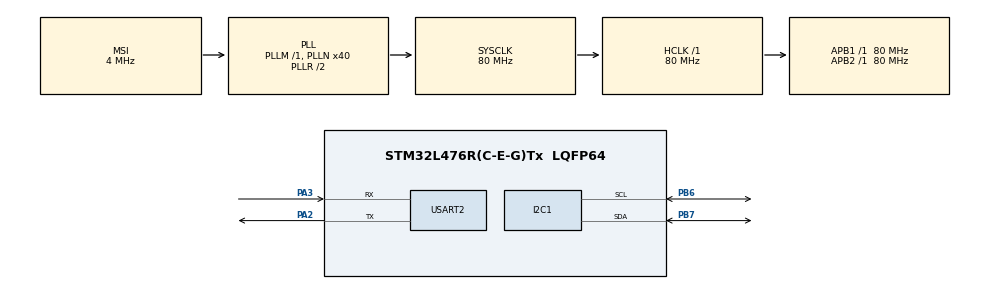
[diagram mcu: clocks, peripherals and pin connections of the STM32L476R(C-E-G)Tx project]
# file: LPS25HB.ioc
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I2C1.Timing=0x10D19CE4
Mcu.Family=STM32L4
Mcu.Name=STM32L476R(C-E-G)Tx
Mcu.Package=LQFP64
NVIC.PriorityGroup=NVIC_PRIORITYGROUP_4
NVIC.USART2_IRQn=true\:15\:0\:true\:false\:true\:true\:true\:true
PA13\ (JTMS-SWDIO).Mode=Serial_Wire
PA13\ (JTMS-SWDIO).Signal=SYS_JTMS-SWDIO
PA14\ (JTCK-SWCLK).Mode=Serial_Wire
PA14\ (JTCK-SWCLK).Signal=SYS_JTCK-SWCLK
PA2.Mode=Asynchronous
PA2.Signal=USART2_TX
PA3.Mode=Asynchronous
PA3.Signal=USART2_RX
PB6.Mode=I2C
PB6.Signal=I2C1_SCL
PB7.Mode=I2C
PB7.Signal=I2C1_SDA
ProjectManager.HeapSize=0x200
ProjectManager.StackSize=0x400
ProjectManager.TargetToolchain=STM32CubeIDE
RCC.AHBFreq_Value=80000000
RCC.APB1Freq_Value=80000000
RCC.APB1TimFreq_Value=80000000
RCC.APB2Freq_Value=80000000
RCC.APB2TimFreq_Value=80000000
RCC.CortexFreq_Value=80000000
RCC.HCLKFreq_Value=80000000
RCC.HSE_VALUE=8000000
RCC.HSI_VALUE=16000000
RCC.LSE_VALUE=32768
RCC.MSI_VALUE=4000000
RCC.PLLN=40
RCC.SYSCLKFreq_VALUE=80000000
RCC.SYSCLKSource=RCC_SYSCLKSOURCE_PLLCLK
RCC.VCOOutputFreq_Value=160000000
USART2.OverrunDisableParam=ADVFEATURE_OVERRUN_DISABLE
USART2.VirtualMode-Asynchronous=VM_ASYNC
board=custom

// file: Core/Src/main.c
/* USER CODE BEGIN Header */
/**
  ******************************************************************************
  * @file           : main.c
  * @brief          : Main program body
  ******************************************************************************
  * @attention
  *
  * Copyright (c) 2026 STMicroelectronics.
  * All rights reserved.
  *
  * This software is licensed under terms that can be found in the LICENSE file
  * in the root directory of this software component.
  * If no LICENSE file comes with this software, it is provided AS-IS.
  *
  ******************************************************************************
  */
/* USER CODE END Header */
#include "main.h"
#include "i2c.h"
#include "usart.h"
#include "gpio.h"

/* USER CODE BEGIN Includes */
#include "stdio.h"

#include "my_uart.h"
#include "LPS25HB.h"
/* USER CODE END Includes */

/* USER CODE BEGIN PD */
#define LODZ_HEIGHT 200.0
#define PRESSURE_OFFSET 1028 - 1021
/* USER CODE END PD */

void SystemClock_Config(void);

int main(void)
{

  /* MCU Configuration--------------------------------------------------------*/

  /* Reset of all peripherals, Initializes the Flash interface and the Systick. */
  HAL_Init();

  /* Configure the system clock */
  SystemClock_Config();

  /* Initialize all configured peripherals */
  MX_GPIO_Init();
  MX_I2C1_Init();
  MX_USART2_UART_Init();
  if(lps_init()){
    printf("Success: LPS25HB was found\n");
  }else{
    printf("Error: LPS25HB was not found\n");
  }
  lps_set_pressure_offset(PRESSURE_OFFSET);
  /* Infinite loop */
  /* USER CODE BEGIN WHILE */
  while (1)
  {
    float abs_pressure_hPa = lps_read_absolute_pressure();
    printf("Temperature: %.1f*C\n", lps_read_temp());
    printf("Absolute Pressure: %.1fhPa\n", abs_pressure_hPa);
    printf("Relative Pressure: %.1fhPa\n", lps_count_relative_pressure(abs_pressure_hPa, LODZ_HEIGHT));
    HAL_Delay(1000);
    /* USER CODE END WHILE */

  }
}

void SystemClock_Config(void)
{
  RCC_OscInitTypeDef RCC_OscInitStruct = {0};
  RCC_ClkInitTypeDef RCC_ClkInitStruct = {0};

  /** Configure the main internal regulator output voltage
  */
  if (HAL_PWREx_ControlVoltageScaling(PWR_REGULATOR_VOLTAGE_SCALE1) != HAL_OK)
  {
    Error_Handler();
  }

  /** Initializes the RCC Oscillators according to the specified parameters
  * in the RCC_OscInitTypeDef structure.
  */
  RCC_OscInitStruct.OscillatorType = RCC_OSCILLATORTYPE_MSI;
  RCC_OscInitStruct.MSIState = RCC_MSI_ON;
  RCC_OscInitStruct.MSICalibrationValue = 0;
  RCC_OscInitStruct.MSIClockRange = RCC_MSIRANGE_6;
  RCC_OscInitStruct.PLL.PLLState = RCC_PLL_ON;
  RCC_OscInitStruct.PLL.PLLSource = RCC_PLLSOURCE_MSI;
  RCC_OscInitStruct.PLL.PLLM = 1;
  RCC_OscInitStruct.PLL.PLLN = 40;
  RCC_OscInitStruct.PLL.PLLP = RCC_PLLP_DIV7;
  RCC_OscInitStruct.PLL.PLLQ = RCC_PLLQ_DIV2;
  RCC_OscInitStruct.PLL.PLLR = RCC_PLLR_DIV2;
  if (HAL_RCC_OscConfig(&RCC_OscInitStruct) != HAL_OK)
  {
    Error_Handler();
  }

  /** Initializes the CPU, AHB and APB buses clocks
  */
  RCC_ClkInitStruct.ClockType = RCC_CLOCKTYPE_HCLK|RCC_CLOCKTYPE_SYSCLK
                              |RCC_CLOCKTYPE_PCLK1|RCC_CLOCKTYPE_PCLK2;
  RCC_ClkInitStruct.SYSCLKSource = RCC_SYSCLKSOURCE_PLLCLK;
  RCC_ClkInitStruct.AHBCLKDivider = RCC_SYSCLK_DIV1;
  RCC_ClkInitStruct.APB1CLKDivider = RCC_HCLK_DIV1;
  RCC_ClkInitStruct.APB2CLKDivider = RCC_HCLK_DIV1;

  if (HAL_RCC_ClockConfig(&RCC_ClkInitStruct, FLASH_LATENCY_4) != HAL_OK)
  {
    Error_Handler();
  }
}

void Error_Handler(void)
{
  __disable_irq();
  while (1)
  {
  }
}
